AUTOSAR XML (schema 4-2-2)
package /Components
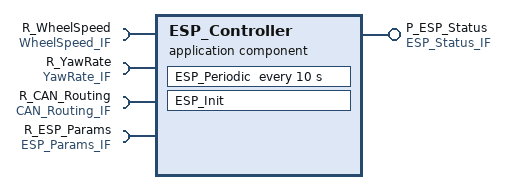
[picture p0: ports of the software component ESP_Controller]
  application sw component type ESP_Controller
    provide port P_ESP_Status: provided-interface=ESP_Status_IF
    4 x require port:
      R_WheelSpeed: required-interface=WheelSpeed_IF
      R_YawRate: required-interface=YawRate_IF
      R_CAN_Routing: required-interface=CAN_Routing_IF
      R_ESP_Params: required-interface=ESP_Params_IF
    behavior ESP_Controller_InternalBehavior
      init event ESP_Init_Event: start-on-event=ESP_Init
      timing event ESP_Periodic_Event: start-on-event=ESP_Periodic, period=10
      runnable ESP_Init
        parameter access PA_Init_ESP_YawGain: accessed-parameter=R_ESP_Params.esp_yaw_gain
        parameter access PA_Init_ESP_SlipThreshold: accessed-parameter=R_ESP_Params.esp_slip_threshold
      runnable ESP_Periodic: minimum-start-interval=10
        data-read-access:
          4 x access:
            VA_Read_WS_FL: accessed-variable=R_WheelSpeed.wheel_speed_fl
            VA_Read_WS_FR: accessed-variable=R_WheelSpeed.wheel_speed_fr
            VA_Read_WS_RL: accessed-variable=R_WheelSpeed.wheel_speed_rl
            VA_Read_WS_RR: accessed-variable=R_WheelSpeed.wheel_speed_rr
        data-receive-point-by-arguments:
          access VRA_Read_YawRate: accessed-variable=R_YawRate.yaw_rate
        data-send-points:
          access VA_Send_ESP_Active: accessed-variable=P_ESP_Status.esp_active
          access VA_Send_ESP_FaultCode: accessed-variable=P_ESP_Status.esp_fault_code
        sync call SCP_Periodic_SendESPCommand: operation=R_CAN_Routing.SendESPCommand, timeout=5
